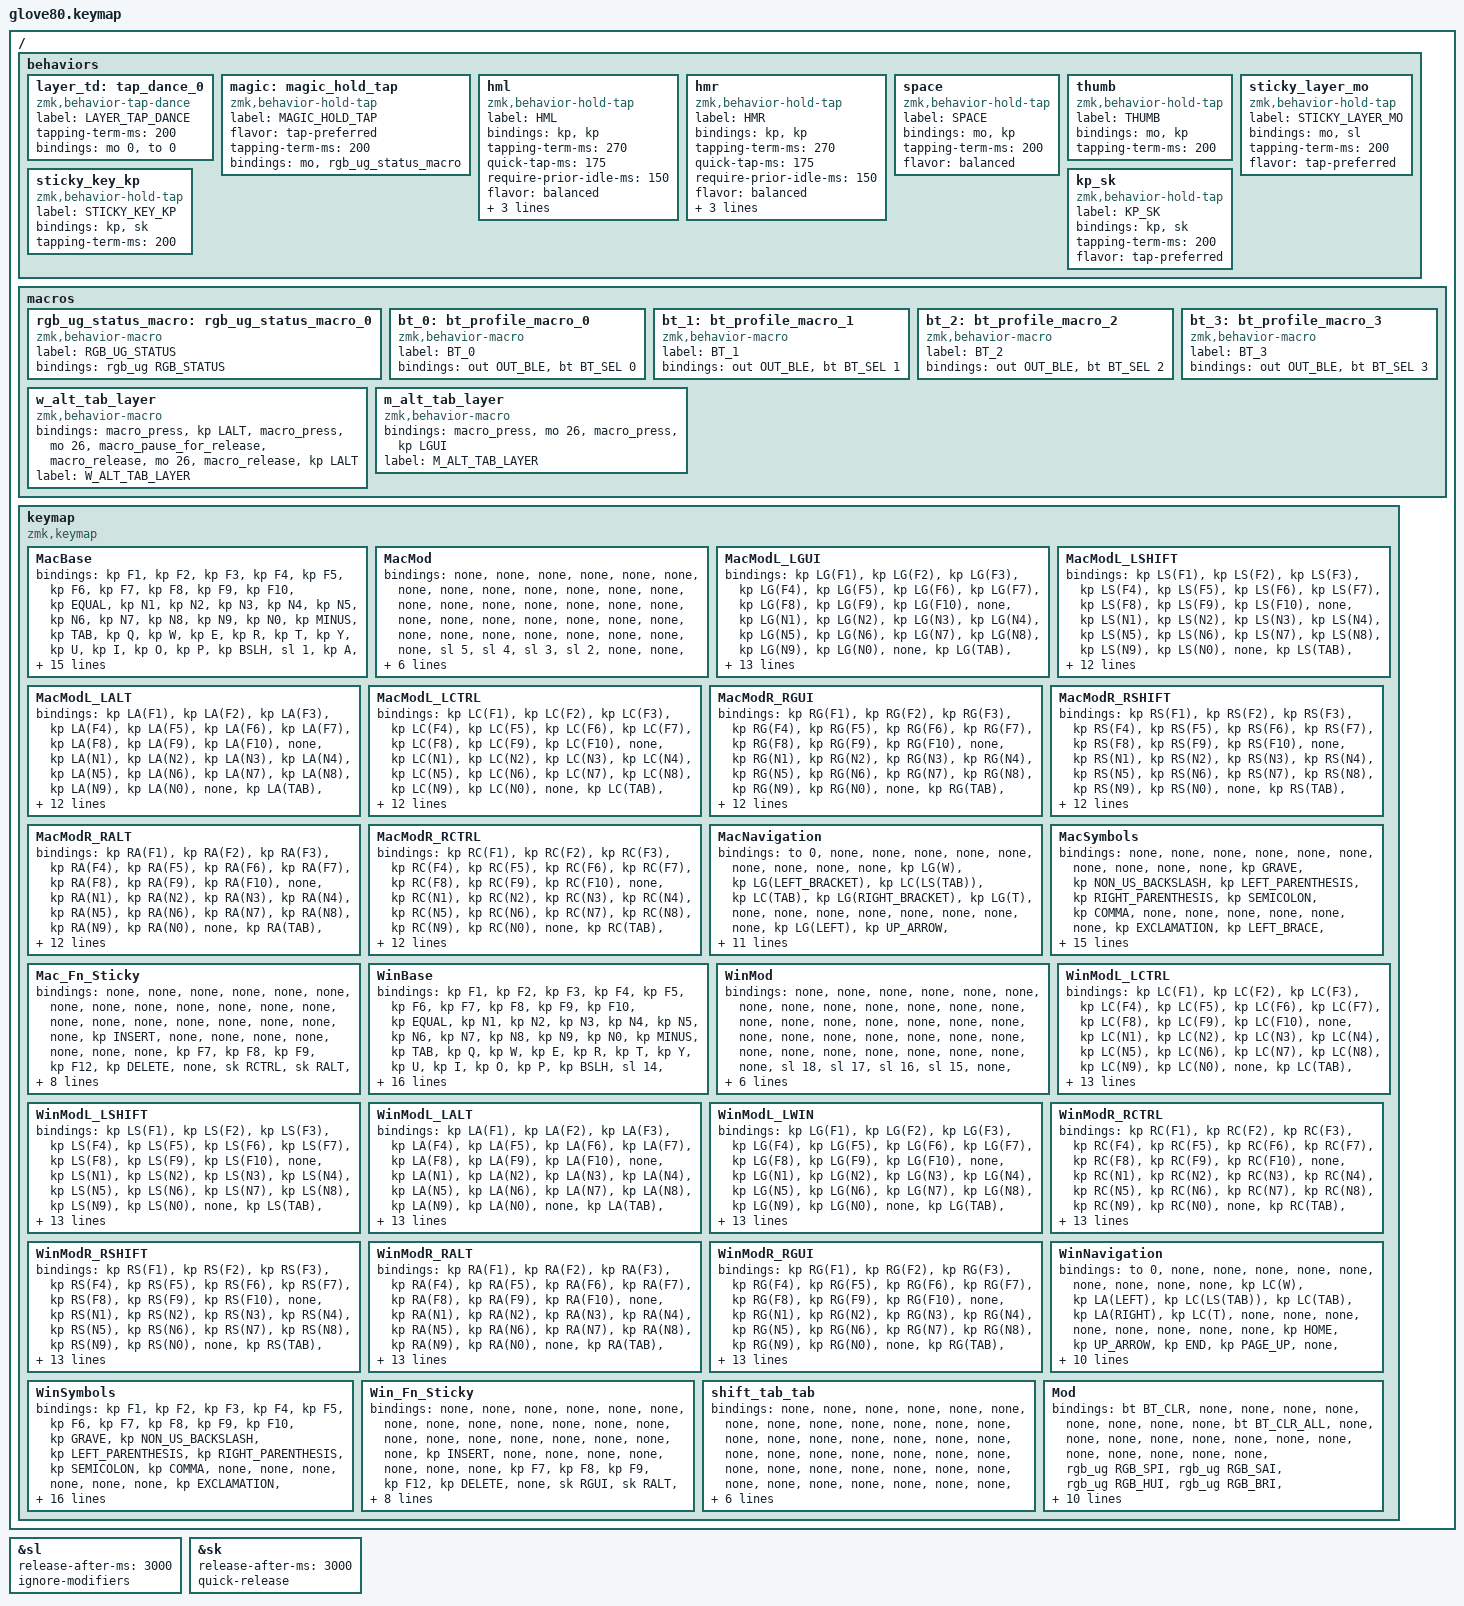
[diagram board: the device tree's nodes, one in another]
/*
 * Copyright (c) 2020 The ZMK Contributors
 *
 * SPDX-License-Identifier: MIT
 */

#include <behaviors.dtsi>
#include <dt-bindings/zmk/bt.h>
#include <dt-bindings/zmk/keys.h>
#include <dt-bindings/zmk/outputs.h>
#include <dt-bindings/zmk/rgb.h>

#define HYPER LC(LS(LG(LALT)))

// layers

#define DEFAULT 0
#define LOWER 1
#define MAGIC 2
#define FACTORY_TEST 3

&sl {
    release-after-ms = <3000>;
    ignore-modifiers;
};

&sk {
    release-after-ms = <3000>;
    quick-release;
};

/ {
    behaviors {
        // For the "layer" key, it'd nice to be able to use it as either a shift or a toggle.
        // Configure it as a tap dance, so the first tap (or hold) is a &mo and the second tap is a &to

        layer_td: tap_dance_0 {
            compatible = "zmk,behavior-tap-dance";
            label = "LAYER_TAP_DANCE";
            #binding-cells = <0>;
            tapping-term-ms = <200>;
            bindings = <&mo 0>, <&to 0>;
        };

        magic: magic_hold_tap {
            compatible = "zmk,behavior-hold-tap";
            label = "MAGIC_HOLD_TAP";
            #binding-cells = <2>;
            flavor = "tap-preferred";
            tapping-term-ms = <200>;
            bindings = <&mo>, <&rgb_ug_status_macro>;
        };

        hml: hml {
            compatible = "zmk,behavior-hold-tap";
            label = "HML";
            bindings = <&kp>, <&kp>;

            #binding-cells = <2>;
            tapping-term-ms = <270>;
            quick-tap-ms = <175>;
            require-prior-idle-ms = <150>;
            flavor = "balanced";
            hold-trigger-key-positions = <5 6 7 8 9 16 17 18 19 20 21 28 29 30 31 32 33 40 41 42 43 44 45 57 58 59 60 61 62 63 73 74 75 76 77 78 79 55 56 57 58 59 60 72 73 74 75 76 52 53 54 69 70 71>;
            hold-trigger-on-release;
        };

        hmr: hmr {
            compatible = "zmk,behavior-hold-tap";
            label = "HMR";
            bindings = <&kp>, <&kp>;

            #binding-cells = <2>;
            tapping-term-ms = <270>;
            quick-tap-ms = <175>;
            require-prior-idle-ms = <150>;
            flavor = "balanced";
            hold-trigger-key-positions = <0 1 2 3 4 10 11 12 13 14 15 22 23 24 25 26 27 34 35 36 37 38 39 46 47 48 49 50 51 52 53 54 64 65 66 67 68 69 70 71 55 56 57 72 73 74>;
            hold-trigger-on-release;
        };

        space: space {
            compatible = "zmk,behavior-hold-tap";
            label = "SPACE";
            bindings = <&mo>, <&kp>;

            #binding-cells = <2>;
            tapping-term-ms = <200>;
            flavor = "balanced";
        };

        thumb: thumb {
            compatible = "zmk,behavior-hold-tap";
            label = "THUMB";
            bindings = <&mo>, <&kp>;

            #binding-cells = <2>;
            tapping-term-ms = <200>;
        };

        sticky_layer_mo: sticky_layer_mo {
            compatible = "zmk,behavior-hold-tap";
            label = "STICKY_LAYER_MO";
            bindings = <&mo>, <&sl>;

            #binding-cells = <2>;
            tapping-term-ms = <200>;
            flavor = "tap-preferred";
        };

        sticky_key_kp: sticky_key_kp {
            compatible = "zmk,behavior-hold-tap";
            label = "STICKY_KEY_KP";
            bindings = <&kp>, <&sk>;

            #binding-cells = <2>;
            tapping-term-ms = <200>;
        };

        kp_sk: kp_sk {
            compatible = "zmk,behavior-hold-tap";
            label = "KP_SK";
            bindings = <&kp>, <&sk>;

            #binding-cells = <2>;
            tapping-term-ms = <200>;
            flavor = "tap-preferred";
        };
    };

    macros {
        rgb_ug_status_macro: rgb_ug_status_macro_0 {
            label = "RGB_UG_STATUS";
            compatible = "zmk,behavior-macro";
            #binding-cells = <0>;
            bindings = <&rgb_ug RGB_STATUS>;
        };

        bt_0: bt_profile_macro_0 {
            label = "BT_0";
            compatible = "zmk,behavior-macro";
            #binding-cells = <0>;
            bindings = <&out OUT_BLE &bt BT_SEL 0>;
        };

        bt_1: bt_profile_macro_1 {
            label = "BT_1";
            compatible = "zmk,behavior-macro";
            #binding-cells = <0>;
            bindings = <&out OUT_BLE &bt BT_SEL 1>;
        };

        bt_2: bt_profile_macro_2 {
            label = "BT_2";
            compatible = "zmk,behavior-macro";
            #binding-cells = <0>;
            bindings = <&out OUT_BLE &bt BT_SEL 2>;
        };

        bt_3: bt_profile_macro_3 {
            label = "BT_3";
            compatible = "zmk,behavior-macro";
            #binding-cells = <0>;
            bindings = <&out OUT_BLE &bt BT_SEL 3>;
        };

        w_alt_tab_layer: w_alt_tab_layer {
            compatible = "zmk,behavior-macro";
            #binding-cells = <0>;
            bindings =
                <&macro_press>,
                <&kp LALT>,
                <&macro_press>,
                <&mo 26>,
                <&macro_pause_for_release>,
                <&macro_release>,
                <&mo 26>,
                <&macro_release>,
                <&kp LALT>;

            label = "W_ALT_TAB_LAYER";
        };

        m_alt_tab_layer: m_alt_tab_layer {
            compatible = "zmk,behavior-macro";
            #binding-cells = <0>;
            bindings = <&macro_press>, <&mo 26>, <&macro_press>, <&kp LGUI>;

            label = "M_ALT_TAB_LAYER";
        };
    };

    keymap {
        compatible = "zmk,keymap";

        MacBase {
            // ---------------------------------------------------------------------------------------------------------------------------------
            // |  F1   |  F2 |  F3 |  F4  |  F5  |                                                               |  F6   |  F7   |  F8  |   F9  |  F10 |
            // |  =    |  1  |  2  |  3   |  4   |  5   |                                                 |  6   |   7   |   8   |  9   |   0   |   -  |
            // |  TAB  |  Q  |  W  |  E   |  R   |  T   |                                                 |  Y   |   U   |   I   |  O   |   P   |   \  |
            // |  ESC  |  A  |  S  |  D   |  F   |  G   |                                                 |  H   |   J   |   K   |  L   |   ;   |   '  |
            // |   `   |  Z  |  X  |  C   |  V   |  B   | LSHFT | LCTRL | LOWER | | LGUI  | RCTRL | RSHFT |  N   |   M   |   ,   |  .   |   /   | PGUP |
            // | MAGIC | HOME| END | LEFT | RIGHT|      | BSPC  | DEL   | LALT  | | RALT  | RET   | SPACE |      |  UP   | DOWN  |  [   |   ]   | PGDN |

            bindings = <
&kp F1                &kp F2                      &kp F3                    &kp F4                        &kp F5                                                                                                                     &kp F6                    &kp F7                        &kp F8                    &kp F9                      &kp F10
&kp EQUAL             &kp N1                      &kp N2                    &kp N3                        &kp N4                    &kp N5                                                                                   &kp N6  &kp N7                    &kp N8                        &kp N9                    &kp N0                      &kp MINUS
&kp TAB               &kp Q                       &kp W                     &kp E                         &kp R                     &kp T                                                                                    &kp Y   &kp U                     &kp I                         &kp O                     &kp P                       &kp BSLH
&sl 1                 &kp A                       &kp S                     &kp D                         &kp F                     &kp G                                                                                    &kp H   &kp J                     &kp K                         &kp L                     &kp SEMI                    &sl 1
&kp_sk LSHIFT LSHIFT  &kp Z                       &kp X                     &kp C                         &kp V                     &kp B   &kp INS              &kp LCTRL  &layer_td  &kp LGUI  &kp RCTRL  &kp ESCAPE       &kp N   &kp M                     &kp COMMA                     &kp DOT                   &kp FSLH                    &kp_sk RSHIFT RSHIFT
&magic 27 0           &sticky_key_kp LCTRL LCTRL  &sticky_key_kp LALT LALT  &sticky_key_kp LSHIFT LSHIFT  &sticky_key_kp LGUI LGUI          &thumb 11 BACKSPACE  &kp DEL    &kp LALT   &kp RALT  &kp RET    &space 10 SPACE          &sticky_key_kp RGUI RGUI  &sticky_key_kp RSHIFT RSHIFT  &sticky_key_kp RALT RALT  &sticky_key_kp LCTRL LCTRL  &kp PG_DN
            >;
        };

        MacMod {
            bindings = <
&none  &none  &none  &none  &none                                                              &none  &none  &none  &none  &none
&none  &none  &none  &none  &none  &none                                                &none  &none  &none  &none  &none  &none
&none  &none  &none  &none  &none  &none                                                &none  &none  &none  &none  &none  &none
&none  &sl 5  &sl 4  &sl 3  &sl 2  &none                                                &none  &sl 6  &sl 7  &sl 8  &sl 9  &none
&none  &none  &none  &none  &none  &none  &kp F24  &none  &none  &none  &none  &kp F24  &none  &none  &none  &none  &none  &none
&none  &none  &none  &none  &none         &kp F24  &none  &none  &none  &none  &kp F24         &none  &none  &none  &none  &none
            >;
        };

        MacModL_LGUI {
            bindings = <
&kp LG(F1)   &kp LG(F2)  &kp LG(F3)  &kp LG(F4)  &kp LG(F5)                                                                                                         &kp LG(F6)  &kp LG(F7)     &kp LG(F8)   &kp LG(F9)    &kp LG(F10)
&none        &kp LG(N1)  &kp LG(N2)  &kp LG(N3)  &kp LG(N4)  &kp LG(N5)                                                                                 &kp LG(N6)  &kp LG(N7)  &kp LG(N8)     &kp LG(N9)   &kp LG(N0)    &none
&kp LG(TAB)  &kp LG(Q)   &kp LG(W)   &kp LG(E)   &kp LG(R)   &kp LG(T)                                                                                  &kp LG(Y)   &kp LG(U)   &kp LG(I)      &kp LG(O)    &kp LG(P)     &none
&none        &sk LCTRL   &sk LALT    &sk LSHIFT  &kp LGUI    &kp LG(G)                                                                                  &kp LG(H)   &kp LG(J)   &kp LG(K)      &kp LG(L)    &kp LG(SEMI)  &none
&none        &kp LG(Z)   &kp LG(X)   &kp LG(C)   &kp LG(V)   &kp LG(B)   &kp F24            &none           &none  &none  &none          &kp F24        &kp LG(N)   &kp LG(M)   &kp LG(COMMA)  &kp LG(DOT)  &kp LG(FSLH)  &none
&none        &none       &none       &none       &none                   &kp LG(BACKSPACE)  &kp LG(DELETE)  &none  &none  &kp LG(ENTER)  &kp LG(SPACE)              &none       &none          &none        &none         &none
            >;
        };

        MacModL_LSHIFT {
            bindings = <
&kp LS(F1)   &kp LS(F2)  &kp LS(F3)  &kp LS(F4)  &kp LS(F5)                                                                        &kp LS(F6)  &kp LS(F7)     &kp LS(F8)   &kp LS(F9)    &kp LS(F10)
&none        &kp LS(N1)  &kp LS(N2)  &kp LS(N3)  &kp LS(N4)  &kp LS(N5)                                                &kp LS(N6)  &kp LS(N7)  &kp LS(N8)     &kp LS(N9)   &kp LS(N0)    &none
&kp LS(TAB)  &kp LS(Q)   &kp LS(W)   &kp LS(E)   &kp LS(R)   &kp LS(T)                                                 &kp LS(Y)   &kp LS(U)   &kp LS(I)      &kp LS(O)    &kp LS(P)     &none
&none        &sk LCTRL   &sk LALT    &kp LSHIFT  &sk LGUI    &kp LS(G)                                                 &kp LS(H)   &kp LS(J)   &kp LS(K)      &kp LS(L)    &kp LS(SEMI)  &none
&none        &kp LS(Z)   &kp LS(X)   &kp LS(C)   &kp LS(V)   &kp LS(B)   &kp F24  &none  &none  &none  &none  &kp F24  &kp LS(N)   &kp LS(M)   &kp LS(COMMA)  &kp LS(DOT)  &kp LS(FSLH)  &none
&none        &none       &none       &none       &none                   &none    &none  &none  &none  &none  &none                &none       &none          &none        &none         &none
            >;
        };

        MacModL_LALT {
            bindings = <
&kp LA(F1)   &kp LA(F2)  &kp LA(F3)  &kp LA(F4)  &kp LA(F5)                                                                        &kp LA(F6)  &kp LA(F7)     &kp LA(F8)   &kp LA(F9)    &kp LA(F10)
&none        &kp LA(N1)  &kp LA(N2)  &kp LA(N3)  &kp LA(N4)  &kp LA(N5)                                                &kp LA(N6)  &kp LA(N7)  &kp LA(N8)     &kp LA(N9)   &kp LA(N0)    &none
&kp LA(TAB)  &kp LA(Q)   &kp LA(W)   &kp LA(E)   &kp LA(R)   &kp LA(T)                                                 &kp LA(Y)   &kp LA(U)   &kp LA(I)      &kp LA(O)    &kp LA(P)     &none
&none        &sk LCTRL   &kp LALT    &sk LSHIFT  &sk LGUI    &kp LA(G)                                                 &kp LA(H)   &kp LA(J)   &kp LA(K)      &kp LA(L)    &kp LA(SEMI)  &none
&none        &kp LA(Z)   &kp LA(X)   &kp LA(C)   &kp LA(V)   &kp LA(B)   &kp F24  &none  &none  &none  &none  &kp F24  &kp LA(N)   &kp LA(M)   &kp LA(COMMA)  &kp LA(DOT)  &kp LA(FSLH)  &none
&none        &none       &none       &none       &none                   &none    &none  &none  &none  &none  &none                &none       &none          &none        &none         &none
            >;
        };

        MacModL_LCTRL {
            bindings = <
&kp LC(F1)   &kp LC(F2)  &kp LC(F3)  &kp LC(F4)  &kp LC(F5)                                                                        &kp LC(F6)  &kp LC(F7)     &kp LC(F8)   &kp LC(F9)    &kp LC(F10)
&none        &kp LC(N1)  &kp LC(N2)  &kp LC(N3)  &kp LC(N4)  &kp LC(N5)                                                &kp LC(N6)  &kp LC(N7)  &kp LC(N8)     &kp LC(N9)   &kp LC(N0)    &none
&kp LC(TAB)  &kp LC(Q)   &kp LC(W)   &kp LC(E)   &kp LC(R)   &kp LC(T)                                                 &kp LC(Y)   &kp LC(U)   &kp LC(I)      &kp LC(O)    &kp LC(P)     &none
&none        &kp LCTRL   &sk LALT    &sk LSHIFT  &sk LGUI    &kp LC(G)                                                 &kp LC(H)   &kp LC(J)   &kp LC(K)      &kp LC(L)    &kp LC(SEMI)  &none
&none        &kp LC(Z)   &kp LC(X)   &kp LC(C)   &kp LC(V)   &kp LC(B)   &kp F24  &none  &none  &none  &none  &kp F24  &kp LC(N)   &kp LC(M)   &kp LC(COMMA)  &kp LC(DOT)  &kp LC(FSLH)  &none
&none        &none       &none       &none       &none                   &none    &none  &none  &none  &none  &none                &none       &none          &none        &none         &none
            >;
        };

        MacModR_RGUI {
            bindings = <
&kp RG(F1)   &kp RG(F2)  &kp RG(F3)  &kp RG(F4)  &kp RG(F5)                                                                        &kp RG(F6)  &kp RG(F7)     &kp RG(F8)   &kp RG(F9)    &kp RG(F10)
&none        &kp RG(N1)  &kp RG(N2)  &kp RG(N3)  &kp RG(N4)  &kp RG(N5)                                                &kp RG(N6)  &kp RG(N7)  &kp RG(N8)     &kp RG(N9)   &kp RG(N0)    &none
&kp RG(TAB)  &kp RG(Q)   &kp RG(W)   &kp RG(E)   &kp RG(R)   &kp RG(T)                                                 &kp RG(Y)   &kp RG(U)   &kp RG(I)      &kp RG(O)    &kp RG(P)     &none
&none        &kp RG(A)   &kp RG(S)   &kp RG(D)   &kp RG(F)   &kp RG(G)                                                 &kp RG(H)   &kp RGUI    &sk RSHIFT     &sk RALT     &sk RCTRL     &none
&none        &kp RG(Z)   &kp RG(X)   &kp RG(C)   &kp RG(V)   &kp RG(B)   &kp F24  &none  &none  &none  &none  &kp F24  &kp RG(N)   &kp RG(M)   &kp RG(COMMA)  &kp LG(DOT)  &kp RG(FSLH)  &none
&none        &none       &none       &none       &none                   &none    &none  &none  &none  &none  &none                &none       &none          &none        &none         &none
            >;
        };

        MacModR_RSHIFT {
            bindings = <
&kp RS(F1)   &kp RS(F2)  &kp RS(F3)  &kp RS(F4)  &kp RS(F5)                                                                        &kp RS(F6)  &kp RS(F7)     &kp RS(F8)   &kp RS(F9)    &kp RS(F10)
&none        &kp RS(N1)  &kp RS(N2)  &kp RS(N3)  &kp RS(N4)  &kp RS(N5)                                                &kp RS(N6)  &kp RS(N7)  &kp RS(N8)     &kp RS(N9)   &kp RS(N0)    &none
&kp RS(TAB)  &kp RS(Q)   &kp RS(W)   &kp RS(E)   &kp RS(R)   &kp RS(T)                                                 &kp RS(Y)   &kp RS(U)   &kp RS(I)      &kp RS(O)    &kp RS(P)     &none
&none        &kp RS(A)   &kp RS(S)   &kp RS(D)   &kp RS(F)   &kp RS(G)                                                 &kp RS(H)   &sk RGUI    &kp RSHIFT     &sk RALT     &sk RCTRL     &none
&none        &kp RS(Z)   &kp RS(X)   &kp RS(C)   &kp RS(V)   &kp RS(B)   &kp F24  &none  &none  &none  &none  &kp F24  &kp RS(N)   &kp RS(M)   &kp RS(COMMA)  &kp RS(DOT)  &kp RS(FSLH)  &none
&none        &none       &none       &none       &none                   &none    &none  &none  &none  &none  &none                &none       &none          &none        &none         &none
            >;
        };

        MacModR_RALT {
            bindings = <
&kp RA(F1)   &kp RA(F2)  &kp RA(F3)  &kp RA(F4)  &kp RA(F5)                                                                        &kp RA(F6)  &kp RA(F7)     &kp RA(F8)   &kp RA(F9)    &kp RA(F10)
&none        &kp RA(N1)  &kp RA(N2)  &kp RA(N3)  &kp RA(N4)  &kp RA(N5)                                                &kp RA(N6)  &kp RA(N7)  &kp RA(N8)     &kp RA(N9)   &kp RA(N0)    &none
&kp RA(TAB)  &kp RA(Q)   &kp RA(W)   &kp RA(E)   &kp RA(R)   &kp RA(T)                                                 &kp RA(Y)   &kp RA(U)   &kp RA(I)      &kp RA(O)    &kp RA(P)     &none
&none        &kp RA(A)   &kp RA(S)   &kp RA(D)   &kp RA(F)   &kp RA(G)                                                 &kp RA(H)   &sk RGUI    &sk RSHIFT     &kp RALT     &sk RCTRL     &none
&none        &kp RA(Z)   &kp RA(X)   &kp RA(C)   &kp RA(V)   &kp RA(B)   &kp F24  &none  &none  &none  &none  &kp F24  &kp RA(N)   &kp RA(M)   &kp RA(COMMA)  &kp RA(DOT)  &kp RA(FSLH)  &none
&none        &none       &none       &none       &none                   &none    &none  &none  &none  &none  &none                &none       &none          &none        &none         &none
            >;
        };

        MacModR_RCTRL {
            bindings = <
&kp RC(F1)   &kp RC(F2)  &kp RC(F3)  &kp RC(F4)  &kp RC(F5)                                                                        &kp RC(F6)  &kp RC(F7)     &kp RC(F8)   &kp RC(F9)    &kp RC(F10)
&none        &kp RC(N1)  &kp RC(N2)  &kp RC(N3)  &kp RC(N4)  &kp RC(N5)                                                &kp RC(N6)  &kp RC(N7)  &kp RC(N8)     &kp RC(N9)   &kp RC(N0)    &none
&kp RC(TAB)  &kp RC(Q)   &kp RC(W)   &kp RC(E)   &kp RC(R)   &kp RC(T)                                                 &kp RC(Y)   &kp RC(U)   &kp RC(I)      &kp RC(O)    &kp RC(P)     &none
&none        &kp RC(A)   &kp RC(S)   &kp RC(D)   &kp RC(F)   &kp RC(G)                                                 &kp RC(H)   &sk RGUI    &sk RSHIFT     &sk RALT     &kp RCTRL     &none
&none        &kp RC(Z)   &kp RC(X)   &kp RC(C)   &kp RC(V)   &kp RC(B)   &kp F24  &none  &none  &none  &none  &kp F24  &kp RC(N)   &kp RC(M)   &kp RC(COMMA)  &kp RC(DOT)  &kp RC(FSLH)  &none
&none        &none       &none       &none       &none                   &none    &none  &none  &none  &none  &none                &none       &none          &none        &none         &none
            >;
        };

        MacNavigation {
            bindings = <
&to 0      &none                 &none            &none         &none                                                                                                     &none          &none       &none         &none      &none
&kp LG(W)  &kp LG(LEFT_BRACKET)  &kp LC(LS(TAB))  &kp LC(TAB)   &kp LG(RIGHT_BRACKET)  &kp LG(T)                                                                   &none  &none          &none       &none         &none      &none
&none      &none                 &kp LG(LEFT)     &kp UP_ARROW  &kp LG(RIGHT)          &kp PAGE_UP                                                                 &none  &kp RG(RS(G))  &kp RG(F)   &kp RG(G)     &none      &none
&none      &none                 &kp LEFT         &kp DOWN      &kp RIGHT              &kp PAGE_DOWN                                                               &none  &kp RALT       &kp RSHIFT  &kp RGUI      &kp RCTRL  &none
&none      &none                 &none            &none         &none                  &none          &none                &none       &none  &none  &none  &none  &none  &none          &none       &none         &none      &none
&none      &none                 &none            &none         &none                                 &thumb 11 BACKSPACE  &kp DELETE  &none  &none  &none  &none         &kp LEFT       &kp DOWN    &kp UP_ARROW  &kp RIGHT  &none
            >;
        };

        MacSymbols {
            bindings = <
&none            &none                 &none                 &none                  &none                                                                                 &none               &none           &none               &none                 &none
&kp GRAVE        &kp NON_US_BACKSLASH  &kp LEFT_PARENTHESIS  &kp RIGHT_PARENTHESIS  &kp SEMICOLON     &kp COMMA                                                    &none  &none               &none           &none               &none                 &none
&kp EXCLAMATION  &kp LEFT_BRACE        &kp SINGLE_QUOTE      &kp DOUBLE_QUOTES      &kp RIGHT_BRACE   &kp QUESTION                                                 &none  &kp N7              &kp N8          &kp N9              &none                 &none
&kp HASH         &hml LCTRL CARET      &hml LALT EQUAL       &hml LSHIFT UNDER      &hml LGUI DOLLAR  &kp STAR                                                     &none  &hmr RGUI NUMBER_4  &hmr RSHIFT N5  &hmr RALT NUMBER_6  &hmr RCTRL SEMICOLON  &kp BSPC
&kp COLON        &kp LESS_THAN         &kp PIPE              &kp MINUS              &kp GREATER_THAN  &kp KP_SLASH  &none  &none  &none  &none  &none      &kp N0  &none  &kp N1              &kp N2          &kp NUMBER_3        &kp SLASH             &none
&kp TILDE        &kp AMPERSAND         &kp LEFT_BRACKET      &kp RIGHT_BRACKET      &kp PLUS                        &none  &none  &none  &none  &kp ENTER  &none          &kp N0              &kp PLUS        &kp MINUS           &none                 &none
            >;
        };

        Mac_Fn_Sticky {
            bindings = <
&none  &none      &none     &none       &none                                                                   &none   &none   &none   &none    &none
&none  &none      &none     &none       &none     &none                                                  &none  &none   &none   &none   &none    &kp INSERT
&none  &none      &none     &none       &none     &none                                                  &none  &kp F7  &kp F8  &kp F9  &kp F12  &kp DELETE
&none  &sk RCTRL  &sk RALT  &sk RSHIFT  &sk RGUI  &none                                                  &none  &kp F4  &kp F5  &kp F6  &kp F11  &kp PRINTSCREEN
&none  &none      &none     &none       &none     &none  &none  &none  &none  &none    &none    &none    &none  &kp F1  &kp F2  &kp F3  &kp F10  &kp SCROLLLOCK
&none  &none      &none     &none       &none            &none  &none  &none  &kp F10  &kp F11  &kp F12         &none   &none   &none   &none    &kp PAUSE_BREAK
            >;
        };

        WinBase {
            bindings = <
&kp F1                &kp F2                    &kp F3                    &kp F4                        &kp F5                                                                                                                       &kp F6                      &kp F7                        &kp F8                    &kp F9                    &kp F10
&kp EQUAL             &kp N1                    &kp N2                    &kp N3                        &kp N4                      &kp N5                                                                                   &kp N6  &kp N7                      &kp N8                        &kp N9                    &kp N0                    &kp MINUS
&kp TAB               &kp Q                     &kp W                     &kp E                         &kp R                       &kp T                                                                                    &kp Y   &kp U                       &kp I                         &kp O                     &kp P                     &kp BSLH
&sl 14                &kp A                     &kp S                     &kp D                         &kp F                       &kp G                                                                                    &kp H   &kp J                       &kp K                         &kp L                     &kp SEMI                  &sl 14
&kp_sk LSHIFT LSHIFT  &kp Z                     &kp X                     &kp C                         &kp V                       &kp B   &kp INS              &kp LCTRL  &layer_td  &kp LGUI  &kp RCTRL  &kp ESCAPE       &kp N   &kp M                       &kp COMMA                     &kp DOT                   &kp FSLH                  &kp_sk RSHIFT RSHIFT
&magic 27 0           &sticky_key_kp LGUI LGUI  &sticky_key_kp LALT LALT  &sticky_key_kp LSHIFT LSHIFT  &sticky_key_kp LCTRL LCTRL          &thumb 11 BACKSPACE  &kp DEL    &kp LALT   &kp RALT  &kp RET    &space 10 SPACE          &sticky_key_kp RCTRL RCTRL  &sticky_key_kp RSHIFT RSHIFT  &sticky_key_kp RALT RALT  &sticky_key_kp RGUI RGUI  &kp PG_DN
            >;
        };

        WinMod {
            bindings = <
&none  &none   &none   &none   &none                                                               &none   &none   &none   &none   &none
&none  &none   &none   &none   &none   &none                                                &none  &none   &none   &none   &none   &none
&none  &none   &none   &none   &none   &none                                                &none  &none   &none   &none   &none   &none
&none  &sl 18  &sl 17  &sl 16  &sl 15  &none                                                &none  &sl 19  &sl 20  &sl 21  &sl 22  &none
&none  &none   &none   &none   &none   &none  &kp F24  &none  &none  &none  &none  &kp F24  &none  &none   &none   &none   &none   &none
&none  &none   &none   &none   &none          &kp F24  &none  &none  &none  &none  &kp F24         &none   &none   &none   &none   &none
            >;
        };

        WinModL_LCTRL {
            bindings = <
&kp LC(F1)   &kp LC(F2)  &kp LC(F3)  &kp LC(F4)  &kp LC(F5)                                                                                                         &kp LC(F6)  &kp LC(F7)     &kp LC(F8)   &kp LC(F9)    &kp LC(F10)
&none        &kp LC(N1)  &kp LC(N2)  &kp LC(N3)  &kp LC(N4)  &kp LC(N5)                                                                                 &kp LC(N6)  &kp LC(N7)  &kp LC(N8)     &kp LC(N9)   &kp LC(N0)    &none
&kp LC(TAB)  &kp LC(Q)   &kp LC(W)   &kp LC(E)   &kp LC(R)   &kp LC(T)                                                                                  &kp LC(Y)   &kp LC(U)   &kp LC(I)      &kp LC(O)    &kp LC(P)     &none
&none        &kp LCTRL   &sk LALT    &sk LSHIFT  &sk LGUI    &kp LC(G)                                                                                  &kp LC(H)   &kp LC(J)   &kp LC(K)      &kp LC(L)    &kp LC(SEMI)  &none
&none        &kp LC(Z)   &kp LC(X)   &kp LC(C)   &kp LC(V)   &kp LC(B)   &kp F24            &none           &none  &none  &none          &kp F24        &kp LC(N)   &kp LC(M)   &kp LC(COMMA)  &kp LC(DOT)  &kp LC(FSLH)  &none
&none        &none       &none       &none       &none                   &kp LC(BACKSPACE)  &kp LC(DELETE)  &none  &none  &kp LC(ENTER)  &kp LC(SPACE)              &none       &none          &none        &none         &none
            >;
        };

        WinModL_LSHIFT {
            bindings = <
&kp LS(F1)   &kp LS(F2)  &kp LS(F3)  &kp LS(F4)  &kp LS(F5)                                                                                                             &kp LS(F6)  &kp LS(F7)     &kp LS(F8)   &kp LS(F9)    &kp LS(F10)
&none        &kp LS(N1)  &kp LS(N2)  &kp LS(N3)  &kp LS(N4)  &kp LS(N5)                                                                                     &kp LS(N6)  &kp LS(N7)  &kp LS(N8)     &kp LS(N9)   &kp LS(N0)    &none
&kp LS(TAB)  &kp LS(Q)   &kp LS(W)   &kp LS(E)   &kp LS(R)   &kp LS(T)                                                                                      &kp LS(Y)   &kp LS(U)   &kp LS(I)      &kp LS(O)    &kp LS(P)     &none
&none        &sk LGUI    &sk LALT    &kp LSHIFT  &sk LCTRL   &kp LS(G)                                                                                      &kp LS(H)   &kp LS(J)   &kp LS(K)      &kp LS(L)    &kp LS(SEMI)  &none
&none        &kp LS(Z)   &kp LS(X)   &kp LS(C)   &kp LS(V)   &kp LS(B)   &kp F24            &none           &none  &none  &none              &kp F24        &kp LS(N)   &kp LS(M)   &kp LS(COMMA)  &kp LS(DOT)  &kp LS(FSLH)  &none
&none        &none       &none       &none       &none                   &kp LS(BACKSPACE)  &kp LS(DELETE)  &none  &none  &kp LS(BACKSPACE)  &kp LS(ENTER)              &none       &none          &none        &none         &none
            >;
        };

        WinModL_LALT {
            bindings = <
&kp LA(F1)   &kp LA(F2)  &kp LA(F3)  &kp LA(F4)  &kp LA(F5)                                                                                                             &kp LA(F6)  &kp LA(F7)     &kp LA(F8)   &kp LA(F9)    &kp LA(F10)
&none        &kp LA(N1)  &kp LA(N2)  &kp LA(N3)  &kp LA(N4)  &kp LA(N5)                                                                                     &kp LA(N6)  &kp LA(N7)  &kp LA(N8)     &kp LA(N9)   &kp LA(N0)    &none
&kp LA(TAB)  &kp LA(Q)   &kp LA(W)   &kp LA(E)   &kp LA(R)   &kp LA(T)                                                                                      &kp LA(Y)   &kp LA(U)   &kp LA(I)      &kp LA(O)    &kp LA(P)     &none
&none        &sk LGUI    &kp LALT    &sk LSHIFT  &sk LCTRL   &kp LA(G)                                                                                      &kp LA(H)   &kp LA(J)   &kp LA(K)      &kp LA(L)    &kp LA(SEMI)  &none
&none        &kp LA(Z)   &kp LA(X)   &kp LA(C)   &kp LA(V)   &kp LA(B)   &kp F24            &none           &none  &none  &none          &kp F24            &kp LA(N)   &kp LA(M)   &kp LA(COMMA)  &kp LA(DOT)  &kp LA(FSLH)  &none
&none        &none       &none       &none       &none                   &kp LA(BACKSPACE)  &kp LA(DELETE)  &none  &none  &kp LA(ENTER)  &kp LA(BACKSPACE)              &none       &none          &none        &none         &none
            >;
        };

        WinModL_LWIN {
            bindings = <
&kp LG(F1)   &kp LG(F2)  &kp LG(F3)  &kp LG(F4)  &kp LG(F5)                                                                                                         &kp LG(F6)  &kp LG(F7)     &kp LG(F8)   &kp LG(F9)    &kp LG(F10)
&none        &kp LG(N1)  &kp LG(N2)  &kp LG(N3)  &kp LG(N4)  &kp LG(N5)                                                                                 &kp LG(N6)  &kp LG(N7)  &kp LG(N8)     &kp LG(N9)   &kp LG(N0)    &none
&kp LG(TAB)  &kp LG(Q)   &kp LG(W)   &kp LG(E)   &kp LG(R)   &kp LG(T)                                                                                  &kp LG(Y)   &kp LG(U)   &kp LG(I)      &kp LG(O)    &kp LG(P)     &none
&none        &kp LGUI    &sk LALT    &sk LSHIFT  &sk LCTRL   &kp LG(G)                                                                                  &kp LG(H)   &kp LG(J)   &kp LG(K)      &kp LG(L)    &kp LG(SEMI)  &none
&none        &kp LG(Z)   &kp LG(X)   &kp LG(C)   &kp LG(V)   &kp LG(B)   &kp F24            &none           &none  &none  &none          &kp F24        &kp LG(N)   &kp LG(M)   &kp LG(COMMA)  &kp LG(DOT)  &kp LG(FSLH)  &none
&none        &none       &none       &none       &none                   &kp LG(BACKSPACE)  &kp LG(DELETE)  &none  &none  &kp LG(ENTER)  &kp LG(SPACE)              &none       &none          &none        &none         &none
            >;
        };

        WinModR_RCTRL {
            bindings = <
&kp RC(F1)   &kp RC(F2)  &kp RC(F3)  &kp RC(F4)  &kp RC(F5)                                                                                                         &kp RC(F6)  &kp RC(F7)     &kp RC(F8)   &kp RC(F9)    &kp RC(F10)
&none        &kp RC(N1)  &kp RC(N2)  &kp RC(N3)  &kp RC(N4)  &kp RC(N5)                                                                                 &kp RC(N6)  &kp RC(N7)  &kp RC(N8)     &kp RC(N9)   &kp RC(N0)    &none
&kp RC(TAB)  &kp RC(Q)   &kp RC(W)   &kp RC(E)   &kp RC(R)   &kp RC(T)                                                                                  &kp RC(Y)   &kp RC(U)   &kp RC(I)      &kp RC(O)    &kp RC(P)     &none
&none        &kp RC(A)   &kp RC(S)   &kp RC(D)   &kp RC(F)   &kp RC(G)                                                                                  &kp RC(H)   &kp RCTRL   &sk RSHIFT     &sk RALT     &sk RGUI      &none
&none        &kp RC(Z)   &kp RC(X)   &kp RC(C)   &kp RC(V)   &kp RC(B)   &kp F24            &none           &none  &none  &none          &kp F24        &kp RC(N)   &kp RC(M)   &kp RC(COMMA)  &kp RC(DOT)  &kp RC(FSLH)  &none
&none        &none       &none       &none       &none                   &kp RC(BACKSPACE)  &kp RC(DELETE)  &none  &none  &kp RC(ENTER)  &kp RC(SPACE)              &none       &none          &none        &none         &none
            >;
        };

        WinModR_RSHIFT {
            bindings = <
&kp RS(F1)   &kp RS(F2)  &kp RS(F3)  &kp RS(F4)  &kp RS(F5)                                                                                                         &kp RS(F6)  &kp RS(F7)     &kp RS(F8)   &kp RS(F9)    &kp RS(F10)
&none        &kp RS(N1)  &kp RS(N2)  &kp RS(N3)  &kp RS(N4)  &kp RS(N5)                                                                                 &kp RS(N6)  &kp RS(N7)  &kp RS(N8)     &kp RS(N9)   &kp RS(N0)    &none
&kp RS(TAB)  &kp RS(Q)   &kp RS(W)   &kp RS(E)   &kp RS(R)   &kp RS(T)                                                                                  &kp RS(Y)   &kp RS(U)   &kp RS(I)      &kp RS(O)    &kp RS(P)     &none
&none        &kp RS(A)   &kp RS(S)   &kp RS(D)   &kp RS(F)   &kp RS(G)                                                                                  &kp RS(H)   &sk RCTRL   &kp RSHIFT     &sk RALT     &sk RGUI      &none
&none        &kp RS(Z)   &kp RS(X)   &kp RS(C)   &kp RS(V)   &kp RS(B)   &kp F24            &none           &none  &none  &none          &kp F24        &kp RS(N)   &kp RS(M)   &kp RS(COMMA)  &kp RS(DOT)  &kp RS(FSLH)  &none
&none        &none       &none       &none       &none                   &kp RS(BACKSPACE)  &kp RS(DELETE)  &none  &none  &kp RS(ENTER)  &kp RS(SPACE)              &none       &none          &none        &none         &none
            >;
        };

        WinModR_RALT {
            bindings = <
&kp RA(F1)   &kp RA(F2)  &kp RA(F3)  &kp RA(F4)  &kp RA(F5)                                                                                                         &kp RA(F6)  &kp RA(F7)     &kp RA(F8)   &kp RA(F9)    &kp RA(F10)
&none        &kp RA(N1)  &kp RA(N2)  &kp RA(N3)  &kp RA(N4)  &kp RA(N5)                                                                                 &kp RA(N6)  &kp RA(N7)  &kp RA(N8)     &kp RA(N9)   &kp RA(N0)    &none
&kp RA(TAB)  &kp RA(Q)   &kp RA(W)   &kp RA(E)   &kp RA(R)   &kp RA(T)                                                                                  &kp RA(Y)   &kp RA(U)   &kp RA(I)      &kp RA(O)    &kp RA(P)     &none
&none        &kp RA(A)   &kp RA(S)   &kp RA(D)   &kp RA(F)   &kp RA(G)                                                                                  &kp RA(H)   &sk RCTRL   &sk RSHIFT     &kp RALT     &sk RGUI      &none
&none        &kp RA(Z)   &kp RA(X)   &kp RA(C)   &kp RA(V)   &kp RA(B)   &kp F24            &none           &none  &none  &none          &kp F24        &kp RA(N)   &kp RA(M)   &kp RA(COMMA)  &kp RA(DOT)  &kp RA(FSLH)  &none
&none        &none       &none       &none       &none                   &kp RA(BACKSPACE)  &kp RA(DELETE)  &none  &none  &kp RA(ENTER)  &kp RA(SPACE)              &none       &none          &none        &none         &none
            >;
        };

        WinModR_RGUI {
            bindings = <
&kp RG(F1)   &kp RG(F2)  &kp RG(F3)  &kp RG(F4)  &kp RG(F5)                                                                                                         &kp RG(F6)  &kp RG(F7)     &kp RG(F8)   &kp RG(F9)    &kp RG(F10)
&none        &kp RG(N1)  &kp RG(N2)  &kp RG(N3)  &kp RG(N4)  &kp RG(N5)                                                                                 &kp RG(N6)  &kp RG(N7)  &kp RG(N8)     &kp RG(N9)   &kp RG(N0)    &none
&kp RG(TAB)  &kp RG(Q)   &kp RG(W)   &kp RG(E)   &kp RG(R)   &kp RG(T)                                                                                  &kp RG(Y)   &kp RG(U)   &kp RG(I)      &kp RG(O)    &kp RG(P)     &none
&none        &kp RG(A)   &kp RG(S)   &kp RG(D)   &kp RG(F)   &kp RG(G)                                                                                  &kp RG(H)   &sk RCTRL   &sk RSHIFT     &sk RALT     &kp RGUI      &none
&none        &kp RG(Z)   &kp RG(X)   &kp RG(C)   &kp RG(V)   &kp RG(B)   &kp F24            &none           &none  &none  &none          &kp F24        &kp RG(N)   &kp RG(M)   &kp RG(COMMA)  &kp LG(DOT)  &kp RG(FSLH)  &none
&none        &none       &none       &none       &none                   &kp RG(BACKSPACE)  &kp RG(DELETE)  &none  &none  &kp RG(ENTER)  &kp RG(SPACE)              &none       &none          &none        &none         &none
            >;
        };

        WinNavigation {
            bindings = <
&to 0      &none         &none            &none         &none                                                                                             &none       &none       &none         &none      &none
&kp LC(W)  &kp LA(LEFT)  &kp LC(LS(TAB))  &kp LC(TAB)   &kp LA(RIGHT)  &kp LC(T)                                                                   &none  &none       &none       &none         &none      &none
&none      &none         &kp HOME         &kp UP_ARROW  &kp END        &kp PAGE_UP                                                                 &none  &kp RS(F3)  &kp RC(F)   &kp F3        &none      &none
&none      &none         &kp LEFT         &kp DOWN      &kp RIGHT      &kp PAGE_DOWN                                                               &none  &kp RCTRL   &kp RSHIFT  &kp RALT      &kp RGUI   &none
&none      &none         &none            &none         &none          &none          &none                &none       &none  &none  &none  &none  &none  &none       &none       &none         &none      &none
&none      &none         &none            &none         &none                         &thumb 11 BACKSPACE  &kp DELETE  &none  &none  &none  &none         &kp LEFT    &kp DOWN    &kp UP_ARROW  &kp RIGHT  &none
            >;
        };

        WinSymbols {
            bindings = <
&kp F1           &kp F2                &kp F3                &kp F4                 &kp F5                                                                                         &kp F6               &kp F7          &kp F8              &kp F9           &kp F10
&kp GRAVE        &kp NON_US_BACKSLASH  &kp LEFT_PARENTHESIS  &kp RIGHT_PARENTHESIS  &kp SEMICOLON      &kp COMMA                                                    &none          &none                &none           &none               &none            &none
&kp EXCLAMATION  &kp LEFT_BRACE        &kp SINGLE_QUOTE      &kp DOUBLE_QUOTES      &kp RIGHT_BRACE    &kp QUESTION                                                 &none          &kp N7               &kp N8          &kp N9              &none            &none
&kp HASH         &hml LGUI CARET       &hml LALT EQUAL       &hml LSHIFT UNDER      &hml LCTRL DOLLAR  &kp STAR                                                     &kp BACKSPACE  &hmr RCTRL NUMBER_4  &hmr RSHIFT N5  &hmr RALT NUMBER_6  &hmr RCTRL RGUI  &kp BSPC
&kp COLON        &kp LESS_THAN         &kp PIPE              &kp MINUS              &kp GREATER_THAN   &kp KP_SLASH  &none  &none  &none  &none  &none      &kp N0  &none          &kp N1               &kp N2          &kp NUMBER_3        &kp SLASH        &none
&kp TILDE        &kp AMPERSAND         &kp LEFT_BRACKET      &kp RIGHT_BRACKET      &kp PLUS                         &none  &none  &none  &none  &kp ENTER  &none                  &kp N0               &kp PLUS        &kp MINUS           &none            &none
            >;
        };

        Win_Fn_Sticky {
            bindings = <
&none  &none     &none     &none       &none                                                                    &none   &none   &none   &none    &none
&none  &none     &none     &none       &none      &none                                                  &none  &none   &none   &none   &none    &kp INSERT
&none  &none     &none     &none       &none      &none                                                  &none  &kp F7  &kp F8  &kp F9  &kp F12  &kp DELETE
&none  &sk RGUI  &sk RALT  &sk RSHIFT  &sk RCTRL  &none                                                  &none  &kp F4  &kp F5  &kp F6  &kp F11  &kp PRINTSCREEN
&none  &none     &none     &none       &none      &none  &none  &none  &none  &none    &none    &none    &none  &kp F1  &kp F2  &kp F3  &kp F10  &kp SCROLLLOCK
&none  &none     &none     &none       &none             &none  &none  &none  &kp F10  &kp F11  &kp F12         &none   &none   &none   &none    &kp PAUSE_BREAK
            >;
        };

        shift_tab_tab {
            bindings = <
&none  &none  &none  &none  &none                                                                          &none  &none  &none  &none  &none
&none  &none  &none  &none  &none  &none                                                            &none  &none  &none  &none  &none  &none
&none  &none  &none  &none  &none  &none                                                            &none  &none  &none  &none  &none  &none
&none  &none  &none  &none  &none  &none                                                            &none  &none  &none  &none  &none  &none
&none  &none  &none  &none  &none  &none  &none        &none    &none  &none  &none        &none    &none  &none  &none  &none  &none  &none
&none  &none  &none  &none  &none         &kp LS(TAB)  &kp TAB  &none  &none  &kp RS(TAB)  &kp TAB         &none  &none  &none  &none  &none
            >;
        };

        Mod {
            bindings = <
&bt BT_CLR   &none            &none            &none            &none                                                                                      &none  &none  &none  &none  &bt BT_CLR_ALL
&none        &none            &none            &none            &none            &none                                                              &none  &none  &none  &none  &none  &none
&none        &rgb_ug RGB_SPI  &rgb_ug RGB_SAI  &rgb_ug RGB_HUI  &rgb_ug RGB_BRI  &rgb_ug RGB_TOG                                                    &none  &none  &none  &none  &none  &none
&bootloader  &rgb_ug RGB_SPD  &rgb_ug RGB_SAD  &rgb_ug RGB_HUD  &rgb_ug RGB_BRD  &rgb_ug RGB_EFF                                                    &none  &none  &none  &none  &none  &bootloader
&sys_reset   &none            &none            &none            &none            &none            &bt_2  &bt_3   &none         &none  &none  &none  &none  &none  &none  &none  &none  &sys_reset
&none        &none            &none            &none            &none                             &to 0  &to 13  &out OUT_USB  &none  &none  &none         &none  &none  &none  &none  &to 0
            >;
        };
    };
};
